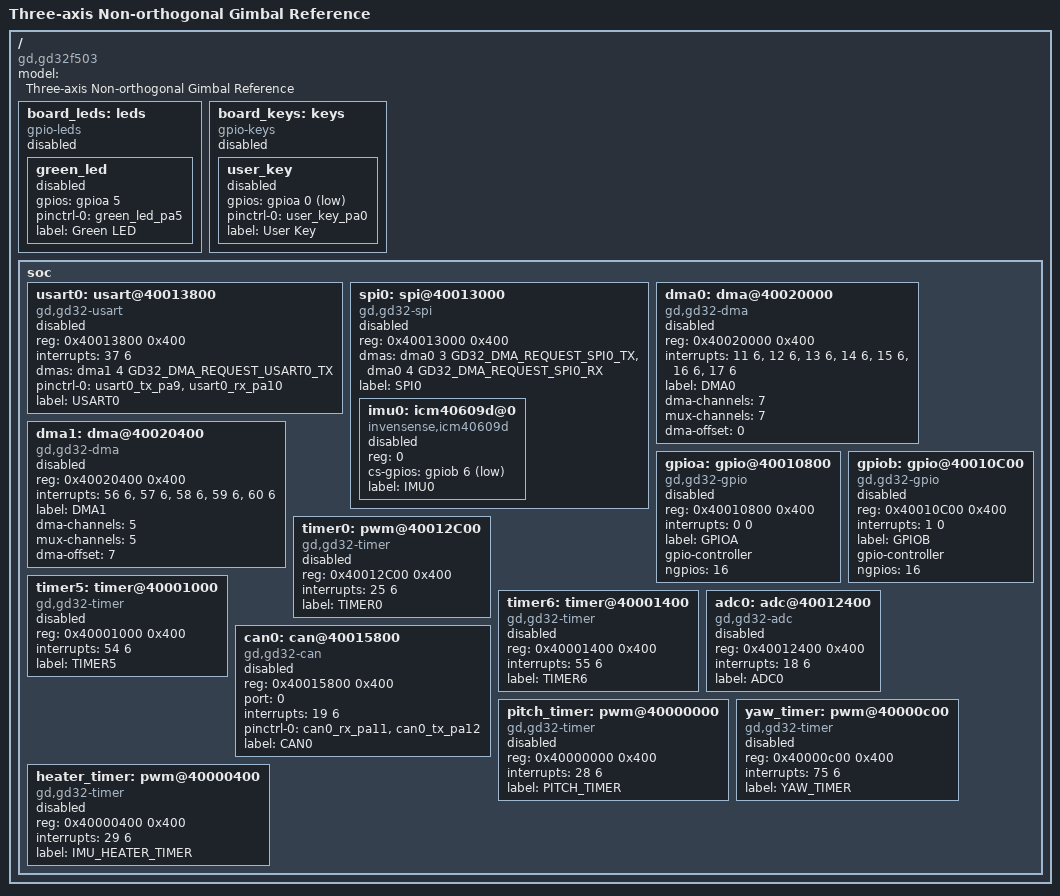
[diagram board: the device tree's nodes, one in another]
/dts-v1/;

/* Shared reference hardware. Firmware overlays opt into peripherals. */

#include <arm/gd/gd32f50x.dtsi>
#include <dt-bindings/dma/gd32_dma.h>
#include <dt-bindings/gpio/gpio.h>
#include <dt-bindings/pinctrl/gd32-pinctrl.h>

/ {
    compatible = "gd,gd32f503";

    board_leds: leds {
        status = "disabled";
        compatible = "gpio-leds";
        green_led: green_led {
            status = "disabled";
            gpios = <&gpioa 5 0>;
            pinctrl-0 = <&green_led_pa5>;
            pinctrl-names = "default";
            label = "Green LED";
        };
    };

    board_keys: keys {
        status = "disabled";
        compatible = "gpio-keys";
        user_key: user_key {
            status = "disabled";
            gpios = <&gpioa 0 (GPIO_ACTIVE_LOW | GPIO_PULL_UP)>;
            pinctrl-0 = <&user_key_pa0>;
            pinctrl-names = "default";
            label = "User Key";
        };
    };

    soc {
        usart0: usart@40013800 {
            status = "disabled";
            compatible = "gd,gd32-usart";
            reg = <0x40013800 0x400>;
            interrupts = <37 6>;
            interrupt-names = "global";
            dmas = <&dma1 4 GD32_DMA_REQUEST_USART0_TX>;
            dma-names = "tx";
            pinctrl-0 = <&usart0_tx_pa9 &usart0_rx_pa10>;
            pinctrl-names = "default";
            label = "USART0";
        };

        spi0: spi@40013000 {
            status = "disabled";
            compatible = "gd,gd32-spi";
            reg = <0x40013000 0x400>;
            dmas = <&dma0 3 GD32_DMA_REQUEST_SPI0_TX>,
                   <&dma0 4 GD32_DMA_REQUEST_SPI0_RX>;
            dma-names = "tx", "rx";
            label = "SPI0";
            #address-cells = <1>;
            #size-cells = <0>;

            imu0: icm40609d@0 {
                status = "disabled";
                compatible = "invensense,icm40609d";
                reg = <0>;
                cs-gpios = <&gpiob 6 1>;
                label = "IMU0";
            };
        };

        dma0: dma@40020000 {
            status = "disabled";
            compatible = "gd,gd32-dma";
            reg = <0x40020000 0x400>;
            interrupts = <11 6>, <12 6>, <13 6>, <14 6>, <15 6>, <16 6>, <17 6>;
            label = "DMA0";
            dma-channels = <7>;
            mux-channels = <7>;
            dma-offset = <0>;
            #dma-cells = <2>;
        };

        dma1: dma@40020400 {
            status = "disabled";
            compatible = "gd,gd32-dma";
            reg = <0x40020400 0x400>;
            interrupts = <56 6>, <57 6>, <58 6>, <59 6>, <60 6>;
            label = "DMA1";
            dma-channels = <5>;
            mux-channels = <5>;
            dma-offset = <7>;
            #dma-cells = <2>;
        };

        gpioa: gpio@40010800 {
            status = "disabled";
            compatible = "gd,gd32-gpio";
            reg = <0x40010800 0x400>;
            interrupts = <0 0>;
            label = "GPIOA";
            gpio-controller;
            #gpio-cells = <2>;
            ngpios = <16>;
        };

        gpiob: gpio@40010C00 {
            status = "disabled";
            compatible = "gd,gd32-gpio";
            reg = <0x40010C00 0x400>;
            interrupts = <1 0>;
            label = "GPIOB";
            gpio-controller;
            #gpio-cells = <2>;
            ngpios = <16>;
        };

        timer0: pwm@40012C00 {
            status = "disabled";
            compatible = "gd,gd32-timer";
            reg = <0x40012C00 0x400>;
            interrupts = <25 6>;
            interrupt-names = "update";
            label = "TIMER0";
            #pwm-cells = <3>;
        };

        timer5: timer@40001000 {
            status = "disabled";
            compatible = "gd,gd32-timer";
            reg = <0x40001000 0x400>;
            interrupts = <54 6>;
            interrupt-names = "update";
            label = "TIMER5";
            #pwm-cells = <3>;
        };

        timer6: timer@40001400 {
            status = "disabled";
            compatible = "gd,gd32-timer";
            reg = <0x40001400 0x400>;
            interrupts = <55 6>;
            interrupt-names = "update";
            label = "TIMER6";
            #pwm-cells = <3>;
        };

        adc0: adc@40012400 {
            status = "disabled";
            compatible = "gd,gd32-adc";
            reg = <0x40012400 0x400>;
            interrupts = <18 6>;
            label = "ADC0";
            #io-channel-cells = <1>;
        };

        can0: can@40015800 {
            status = "disabled";
            compatible = "gd,gd32-can";
            reg = <0x40015800 0x400>;
            port = <0>;
            interrupts = <19 6>;
            pinctrl-0 = <&can0_rx_pa11 &can0_tx_pa12>;
            pinctrl-names = "default";
            label = "CAN0";
        };

    };
};
#include "pinctrl.dtsi"

/ {
    model = "Three-axis Non-orthogonal Gimbal Reference";
    soc {
        pitch_timer: pwm@40000000 {
            compatible = "gd,gd32-timer";
            reg = <0x40000000 0x400>;
            interrupts = <28 6>;
            interrupt-names = "update";
            status = "disabled";
            label = "PITCH_TIMER";
            #pwm-cells = <3>;
        };
        yaw_timer: pwm@40000c00 {
            compatible = "gd,gd32-timer";
            reg = <0x40000c00 0x400>;
            interrupts = <75 6>;
            interrupt-names = "update";
            status = "disabled";
            label = "YAW_TIMER";
            #pwm-cells = <3>;
        };
        heater_timer: pwm@40000400 {
            compatible = "gd,gd32-timer";
            reg = <0x40000400 0x400>;
            interrupts = <29 6>;
            interrupt-names = "update";
            status = "disabled";
            label = "IMU_HEATER_TIMER";
            #pwm-cells = <3>;
        };
    };
};
